# StarFive VisionFive 2 v1.2A register map
File version: 0.1
Registers are 32-bit, read-write, reset 0x0 unless marked. A register's access mark holds for its fields unless they carry their own. Offsets are from the block's base; [hi:lo] are bit positions; 'fields as' and 'values as' point back to an identical list.

## i2c0 — From snps,designware-i2c, peripheral generator
Base 0x10030000
Same registers: i2c1 0x10040000, i2c2 0x10050000, i2c3 0x12030000, i2c4 0x12040000, i2c5 0x12050000, i2c6 0x12060000
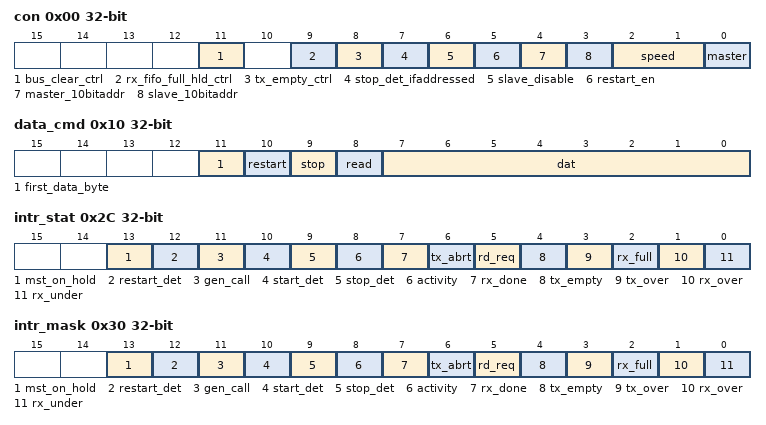
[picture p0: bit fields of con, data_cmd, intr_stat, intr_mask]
0x00 con — DesignWare I2C CON
  [11] bus_clear_ctrl — I2C Bus Clear Control - 0: False, 1: True
  [9] rx_fifo_full_hld_ctrl — I2C RX FIFO Full Hold Control - 0: False, 1: True
  [8] tx_empty_ctrl — I2C TX Empty Control - 0: False, 1: True
  [7] stop_det_ifaddressed — I2C Stop DET If Addressed - 0: False, 1: True
  [6] slave_disable — I2C Slave Disable - 0: False, 1: True
  [5] restart_en — I2C Restart Enable - 0: False, 1: True
  [4] master_10bitaddr — I2C Master 10-bit Address - 0: False, 1: True
  [3] slave_10bitaddr — I2C Slave 10-bit Address - 0: False, 1: True
  [2:1] speed — I2C Speed - 01: Standard, 10: Fast, 11: High
  [0] master — I2C Master Connection - 0: Slave, 1: Master
0x04 tar — DesignWare I2C TAR
  [12] mode — Target addressing mode - 0: 7-bit, 1: 10-bit
  [6:0] address_7bit — Target address, 7-bit mode
  [9:0] address_10bit — Target address, 10-bit mode
0x08 sar — DesignWare I2C SAR
  [6:0] address_7bit — Slave address, 7-bit mode
  [9:0] address_10bit — Slave address, 10-bit mode
0x10 data_cmd — DesignWare I2C Data Command
  [11] first_data_byte — Data Command First Data Byte - 0: False, 1: True
  [10] restart — Data Command RESTART Bit - 0: Do not restart the transfer, 1: Restart the transfer
  [9] stop — Data Command STOP Bit - 0: Non-terminal DATA command byte, 1: Terminal DATA command byte
  [8] read — Data Command READ Bit - 0: Write, 1: Read
  [7:0] dat — Data Command Data Byte
0x14 ss_scl_hcnt — DesignWare I2C SS SCL HCNT
0x18 ss_scl_lcnt — DesignWare I2C SS SCL LCNT
0x1C fs_scl_hcnt — DesignWare I2C FS SCL HCNT
0x20 fs_scl_lcnt — DesignWare I2C FS SCL LCNT
0x24 hs_scl_hcnt — DesignWare I2C HS SCL HCNT
0x28 hs_scl_lcnt — DesignWare I2C HS SCL LCNT
0x2C intr_stat — DesignWare I2C Interrupt Status
  [13] mst_on_hold ro — Master on Hold
  [12] restart_det ro
  [11] gen_call ro — General Call
  [10] start_det ro
  [9] stop_det ro
  [8] activity ro
  [7] rx_done ro
  [6] tx_abrt ro — TX Abort
  [5] rd_req ro — Read Request
  [4] tx_empty ro — TX FIFO Empty
  [3] tx_over ro — TX FIFO Overrun
  [2] rx_full ro — RX FIFO Full
  [1] rx_over ro — RX FIFO Overrun
  [0] rx_under ro — RX FIFO Underrun
0x30 intr_mask — DesignWare I2C Interrupt Mask
  [13] mst_on_hold — Master on Hold
  [12] restart_det
  [11] gen_call — General Call
  [10] start_det
  [9] stop_det
  [8] activity
  [7] rx_done
  [6] tx_abrt — TX Abort
  [5] rd_req — Read Request
  [4] tx_empty — TX FIFO Empty
  [3] tx_over — TX FIFO Overrun
  [2] rx_full — RX FIFO Full
  [1] rx_over — RX FIFO Overrun
  [0] rx_under — RX FIFO Underrun
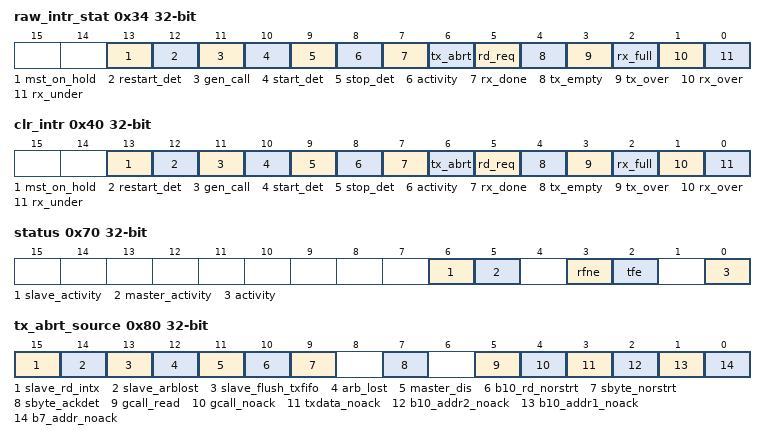
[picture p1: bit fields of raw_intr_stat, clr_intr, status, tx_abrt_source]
0x34 raw_intr_stat — DesignWare I2C Raw Interrupt Status
  fields as intr_stat
0x38 rx_tl — DesignWare I2C RX TL
0x3C tx_tl — DesignWare I2C TX TL
0x40 clr_intr — DesignWare I2C Clear Interrrupt
  fields as intr_mask
0x44 clr_rx_under — DesignWare I2C Clear RX Underrun
0x48 clr_rx_over — DesignWare I2C Clear RX Overrun
0x4C clr_tx_over — DesignWare I2C Clear TX Overrun
0x50 clr_rd_req — DesignWare I2C Clear Read Request
0x54 clr_tx_abrt — DesignWare I2C Clear TX Abort
0x58 clr_rx_done — DesignWare I2C Clear RX Done
0x5C clr_activity — DesignWare I2C Clear Activity
0x60 clr_stop_det — DesignWare I2C Clear Stop DET
0x64 clr_start_det — DesignWare I2C Clear Start DET
0x68 clr_gen_call — DesignWare I2C Clear General Call
0x6C enable — DesignWare I2C Enable
  [1] abort
0x70 status — DesignWare I2C Status
  [6] slave_activity ro, [5] master_activity ro, [3] rfne ro, [2] tfe ro, [0] activity ro
0x74 txflr — DesignWare I2C TX Failure
0x78 rxflr — DesignWare I2C RX Failure
0x7C sda_hold — DesignWare I2C SDA Hold
0x80 tx_abrt_source — DesignWare I2C TX Abort Source
  [15] slave_rd_intx ro, [14] slave_arblost ro, [13] slave_flush_txfifo ro, [12] arb_lost ro, [11] master_dis ro, [10] b10_rd_norstrt ro, [9] sbyte_norstrt ro, [7] sbyte_ackdet ro, [5] gcall_read ro, [4] gcall_noack ro, [3] txdata_noack ro, [2] b10_addr2_noack ro, [1] b10_addr1_noack ro, [0] b7_addr_noack ro
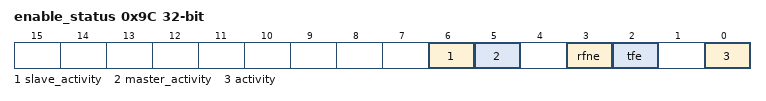
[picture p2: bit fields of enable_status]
0x9C enable_status — DesignWare I2C Enable Status
  [6] slave_activity, [5] master_activity, [3] rfne, [2] tfe, [0] activity
0xA8 clr_restart_det — DesignWare I2C Clear Restart DET
0xF4 comp_param_1 — DesignWare I2C Compatibility Parameter 1
  [3:2] speed ro — Speed mask - 01: Standard, 10: Full, 11: High
0xF8 comp_version — DesignWare I2C Compatibility Version
  [31:0] comp_version ro
0xFC comp_type — DesignWare I2C Compatibility Type
  [31:0] comp_type ro
